AUTOSAR XML (schema 00044)
package /SwComponentType
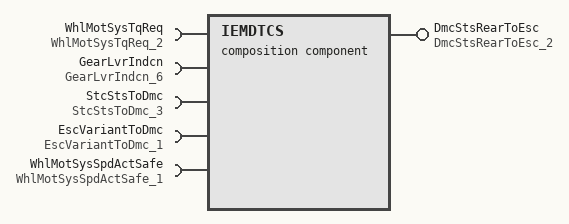
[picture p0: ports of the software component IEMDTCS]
  composition sw component type IEMDTCS
    provide port DmcStsRearToEsc: nonqueued-sender-com-spec{data-element=DmcStsRearToEsc, uses-end-to-end-protection=true, init-value=constant-reference=DmcStsRearToEsc_2}, provided-interface=DmcStsRearToEsc_2
    5 x require port:
      WhlMotSysTqReq: nonqueued-receiver-com-spec{data-element=WhlMotSysTqReq, init-value=constant-reference=WhlMotSysTqReq_2}, required-interface=WhlMotSysTqReq_2
      GearLvrIndcn: nonqueued-receiver-com-spec{data-element=GearLvrIndcn, init-value=constant-reference=GearLvrIndcn_6}, required-interface=GearLvrIndcn_6
      StcStsToDmc: nonqueued-receiver-com-spec{data-element=StcStsToDmc, uses-end-to-end-protection=true, init-value=constant-reference=StcStsToDmc_3}, required-interface=StcStsToDmc_3
      EscVariantToDmc: nonqueued-receiver-com-spec{data-element=EscVariantToDmc, uses-end-to-end-protection=true, init-value=constant-reference=EscVariantToDmc_1}, required-interface=EscVariantToDmc_1
      WhlMotSysSpdActSafe: nonqueued-receiver-com-spec{data-element=WhlMotSysSpdActSafe, uses-end-to-end-protection=true, init-value=constant-reference=WhlMotSysSpdActSafe_1}, required-interface=WhlMotSysSpdActSafe_1
